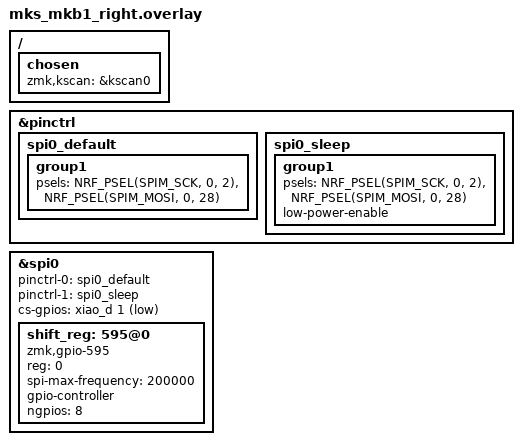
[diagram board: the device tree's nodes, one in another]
#include <dt-bindings/pinctrl/nrf-pinctrl.h>
#include "mks_mkb1.dtsi"

&pinctrl {
    spi0_default: spi0_default {
        group1 {
            psels = <NRF_PSEL(SPIM_SCK, 0, 2)>,
                    <NRF_PSEL(SPIM_MOSI, 0, 28)>;
        };
    };

    spi0_sleep: spi0_sleep {
        group1 {
            psels = <NRF_PSEL(SPIM_SCK, 0, 2)>,
                    <NRF_PSEL(SPIM_MOSI, 0, 28)>;
            low-power-enable;
        };
    };
};

/ {
    chosen {
        zmk,kscan = &kscan0;
    };
};

&spi0 {
    status = "okay";
    pinctrl-0 = <&spi0_default>;
    pinctrl-1 = <&spi0_sleep>;
    pinctrl-names = "default", "sleep";
    cs-gpios = <&xiao_d 1 GPIO_ACTIVE_LOW>;

    shift_reg: 595@0 {
        compatible = "zmk,gpio-595";
        status = "okay";
        reg = <0>;
        spi-max-frequency = <200000>;
        gpio-controller;
        #gpio-cells = <2>;
        ngpios = <8>;
    };
};
